# R7KA8D2AD register map
Vendor: Renesas Electronics Corporation; Series: RA8; File version: 1.10.02
CPU: CM85 r0p2, little endian, MPU, FPU, VTOR, 4 interrupt priority bits, 96 interrupts
Registers are 32-bit, read-write, reset 0x0 unless marked. A register's access mark holds for its fields unless they carry their own. Offsets are from the block's base; [hi:lo] are bit positions; {n}, {i} and the like mark numbered series; 'fields as' and 'values as' point back to an identical list.

## PDMIF — Pulse Density Modulator Interface
Base 0x40256000
Same registers: PDMIF_NS 0x50256000
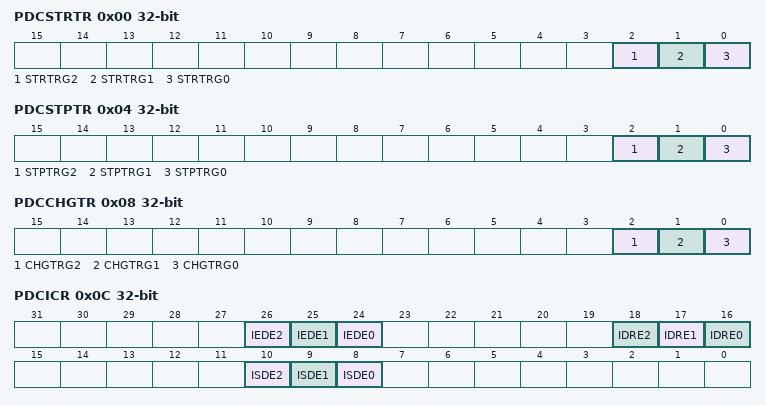
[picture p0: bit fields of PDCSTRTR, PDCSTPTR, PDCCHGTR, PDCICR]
0x00 PDCSTRTR wo — Channel Software Start Trigger Register
  [2] STRTRG2 — Channel 2 Start Trigger
    0=Do nothing; 1=Start channel 2
  [1] STRTRG1 — Channel 1 Start Trigger
    0=Do nothing; 1=Start channel 1
  [0] STRTRG0 — Channel 0 Start Trigger
    0=Do nothing; 1=Start channel 0
0x04 PDCSTPTR wo — Channel Software Stop Trigger Register
  [2] STPTRG2 — Channel 2 Stop Trigger
    0=Do nothing; 1=Stop channel 2
  [1] STPTRG1 — Channel 1 Stop Trigger
    0=Do nothing; 1=Stop channel 1
  [0] STPTRG0 — Channel 0 Stop Trigger
    0=Do nothing; 1=Stop channel 0
0x08 PDCCHGTR wo — Channel Software Change Trigger Register
  [2] CHGTRG2 — Channel 2 Change Trigger
    0=Do nothing; 1=Change clock (PDM_CLK2) setting
  [1] CHGTRG1 — Channel 1 Change Trigger
    0=Do nothing; 1=Change clock (PDM_CLK1) setting
  [0] CHGTRG0 — Channel 0 Change Trigger
    0=Do nothing; 1=Change clock (PDM_CLK0) setting
0x0C PDCICR — Channel Interrupt Control Register
  [26] IEDE2 — Channel 2 Error Detection Interrupt Enable Bit
    0=Do not allow PDM_ERR2 interrupt to be issued; 1=Allow PDM_ERR2 interrupt to be issued
  [25] IEDE1 — Channel 1 Error Detection Interrupt Enable Bit
    0=Do not allow PDM_ERR1 interrupt to be issued; 1=Allow PDM_ERR1 interrupt to be issued
  [24] IEDE0 — Channel 0 Error Detection Interrupt Enable Bit
    0=Do not allow PDM_ERR0 interrupt to be issued; 1=Allow PDM_ERR0 interrupt to be issued
  [18] IDRE2 — Channel 2 Data Reception Interrupt Enable Bit
    0=Do not allow PDM_DAT2 interrupt to be issued; 1=Allow PDM_DAT2 interrupt to be issued
  [17] IDRE1 — Channel 1 Data Reception Interrupt Enable Bit
    0=Do not allow PDM_DAT1 interrupt to be issued; 1=Allow PDM_DAT1 interrupt to be issued
  [16] IDRE0 — Channel 0 Data Reception Interrupt Enable Bit
    0=Do not allow PDM_DAT0 interrupt to be issued; 1=Allow PDM_DAT0 interrupt to be issued
  [10] ISDE2 — Channel 2 Sound Detection Interrupt Enable Bit
    0=Do not allow PDM_SDET interrupt to be issued when the sound for channel 2 is detected; 1=Allow PDM_SDET interrupt to be issued when the sound for channel 2 is detected
  [9] ISDE1 — Channel 1 Sound Detection Interrupt Enable Bit
    0=Do not allow PDM_SDET interrupt to be issued when the sound for channel 1 is detected; 1=Allow PDM_SDET interrupt to be issued when the sound for channel 1 is detected
  [8] ISDE0 — Channel 0 Sound Detection Interrupt Enable Bit
    0=Do not allow PDM_SDET interrupt to be issued when the sound for channel 0 is detected; 1=Allow PDM_SDET interrupt to be issued when the sound for channel 0 is detected
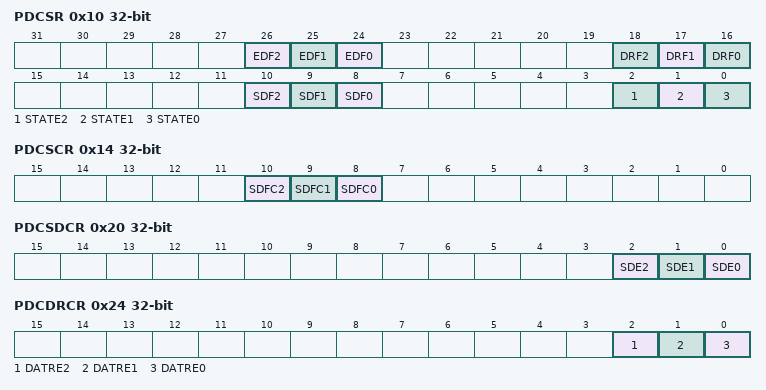
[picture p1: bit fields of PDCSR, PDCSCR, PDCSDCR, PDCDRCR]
0x10 PDCSR ro — Channel Status Register
  [26] EDF2 — Channel 2 Error Detection Flag
    0=Indicates that errors are not detected; 1=Indicates that errors are detected. See 1.2.17Status Register (PDSR) for details.
  [25] EDF1 — Channel 1 Error Detection Flag
    values as EDF2
  [24] EDF0 — Channel 0 Error Detection Flag
    values as EDF2
  [18] DRF2 — Channel 2 Data Reception Flag
    0=Indicates that the number of data stored in buffer does not exceed the threshold; 1=Indicates that the number of data stored in buffer exceeded the threshold
  [17] DRF1 — Channel 1 Data Reception Flag
    values as DRF2
  [16] DRF0 — Channel 0 Data Reception Flag
    values as DRF2
  [10] SDF2 — Channel 2 Sound Detection Flag
    0=Indicates that the sound which exceeded the threshold is not detected; 1=Indicates that the sound which exceeded the threshold is detected
  [9] SDF1 — Channel 1 Sound Detection Flag
    values as SDF2
  [8] SDF0 — Channel 0 Sound Detection Flag
    values as SDF2
  [2] STATE2 — Channel 2 State
    0=Channel 2 stop; 1=Channel 2 in operation
  [1] STATE1 — Channel 1 State
    0=Channel 1 stop; 1=Channel 1 in operation
  [0] STATE0 — Channel 0 State
    0=Channel 0 stop; 1=Channel 0 in operation
0x14 PDCSCR wo — Channel Status Clear Register
  [10] SDFC2 — Channel 2 Sound Detection Flag Clear
    0=Do nothing; 1=Clear PDCSR.SDF2
  [9] SDFC1 — Channel 1 Sound Detection Flag Clear
    0=Do nothing; 1=Clear PDCSR.SDF1
  [8] SDFC0 — Channel 0 Sound Detection Flag Clear
    0=Do nothing; 1=Clear PDCSR.SDF0
0x20 PDCSDCR — Channel Sound Detection Control Register
  [all] fields
    0=Do not allow sound detection; 1=Allow sound detection
  [2] SDE2 — Channel 2 Sound Detection Enable Bit
  [1] SDE1 — Channel 1 Sound Detection Enable Bit
  [0] SDE0 — Channel 0 Sound Detection Enable Bit
0x24 PDCDRCR — Channel Data Read Control Register
  [all] fields
    0=Do not allow reading data from data buffer; 1=Allow reading data from data buffer
  [2] DATRE2 — Channel 2 Data Read Enable Bit
  [1] DATRE1 — Channel 1 Data Read Enable Bit
  [0] DATRE0 — Channel 0 Data Read Enable Bit
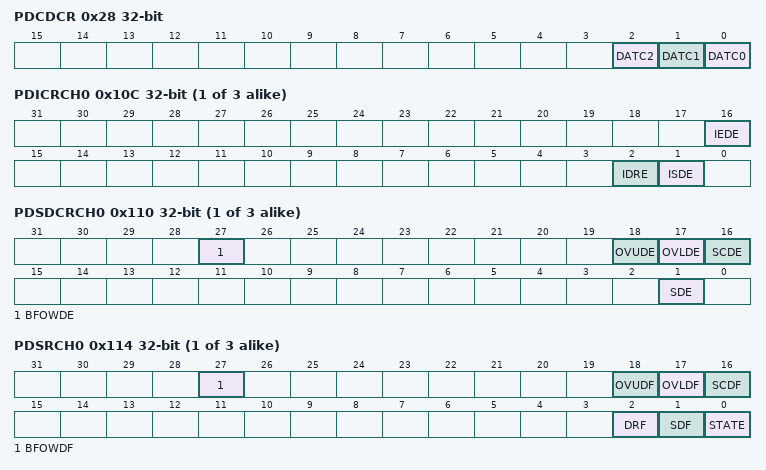
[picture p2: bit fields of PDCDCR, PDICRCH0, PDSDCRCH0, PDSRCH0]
0x28 PDCDCR wo — Channel Data Clear Register
  [all] fields
    0=Do nothing; 1=Clear data
  [2] DATC2 — Channel 2 Data Clear
  [1] DATC1 — Channel 1 Data Clear
  [0] DATC0 — Channel 0 Data Clear
0x80 PDVR ro reset 0x10 — Version Register
  [11:0] VER — PDM-IF version is shown.
{0x100+0x100*i} PDSTRTRCH{i} (i=0..2) wo — Software Start Trigger Register Channel {i}
  [0] STRTRG — Start Trigger
    0=Do nothing; 1=Start the channel
{0x104+0x100*i} PDSTPTRCH{i} (i=0..2) wo — Software Stop Trigger Register Channel {i}
  [0] STPTRG — Stop Trigger
    0=Do nothing; 1=Stop the channel
{0x108+0x100*i} PDCHGTRCH{i} (i=0..2) wo — Software Change Trigger Register Channel {i}
  [0] CHGTRG — Change Trigger
    0=Do nothing; 1=Change settings of PDM_CLKn and sinc filter
{0x10C+0x100*i} PDICRCH{i} (i=0..2) — Interrupt Control Register Channel {i}
  [16] IEDE — Error Detection Interrupt Enable Bit
    0=Do not allow PDM_ERRn interrupt to be issued; 1=Allow PDM_ERRn interrupt to be issued
  [2] IDRE — Data Reception Interrupt Enable Bit
    0=Do not allow PDM_DATn interrupt to be issued; 1=Allow PDM_DATn interrupt to be issued
  [1] ISDE — Sound Detection Interrupt Enable Bit
    0=Do not allow PDM_SDET interrupt to be issued; 1=Allow PDM_SDET interrupt to be issued
{0x110+0x100*i} PDSDCRCH{i} (i=0..2) — Status Detection Control Register Channel {i}
  [27] BFOWDE — Buffer Overwriting Detection Enable Bit
    0=Do not allow detection of buffer overwriting; 1=Allow detection of buffer overwriting
  [18] OVUDE — Overvoltage Upper Limit Exceeded Detection Enable Bit
    0=Do not allow detection of data exceeded upper limit; 1=Allow detection of data exceeded upper limit
  [17] OVLDE — Overvoltage Lower Limit Exceeded Detection Enable Bit
    0=Do not allow detection of data fallen lower limit; 1=Allow detection of data fallen lower limit
  [16] SCDE — Short Circuit Detection Enable Bit
    0=Do not allow detection of the PDM_DATAn pin short circuit; 1=Allow detection of the PDM_DATAn pin short circuit
  [1] SDE — Sound Detection Enable Bit
    0=Do not allow sound detection; 1=Allow sound detection
{0x114+0x100*i} PDSRCH{i} (i=0..2) ro — Status Register Channel {i}
  [27] BFOWDF — Buffer Overwriting Detection Flag
    0=Indicates that buffer overwriting does not occur; 1=Indicates that buffer overwriting occurs
  [18] OVUDF — Overvoltage Upper Limit Exceeded Detection Flag
    0=Indicates that the data has not exceeded the upper limit; 1=Indicates that the data has exceeded the upper limit
  [17] OVLDF — Overvoltage Lower Limit Exceeded Detection Flag
    0=Indicates that the data is not lower than the lower limit; 1=Indicates that the data has fallen the lower limit
  [16] SCDF — Short circuit detection flag.
    0=Indicates that the PDM_DATAn pin short circuit is not detected; 1=Indicates that a short circuit on the PDM_DATAn pin has been detected
  [2] DRF — Data Reception Flag
    0=Indicates that the number of data stored in buffer is lower than a threshold; 1=Indicates that the number of data stored in buffer is higher than or equal to a threshold
  [1] SDF — Sound Detection Flag
    0=Indicates that the sound is not detected; 1=Indicates that the sound is detected
  [0] STATE
    0=Channel stop; 1=Channel in operation
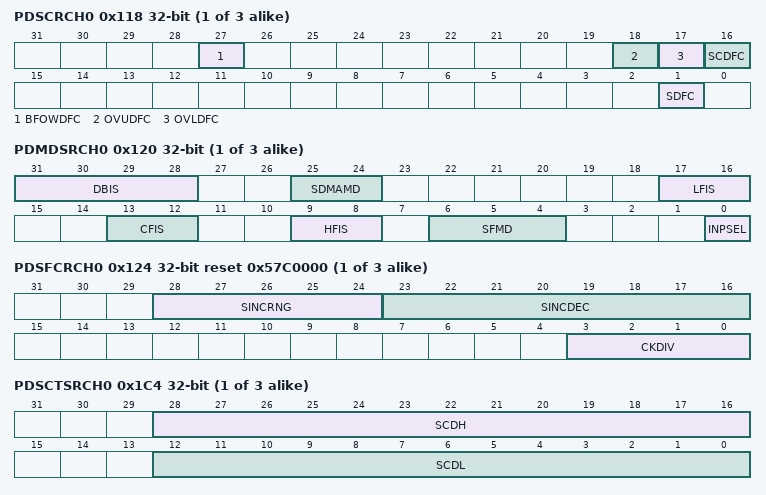
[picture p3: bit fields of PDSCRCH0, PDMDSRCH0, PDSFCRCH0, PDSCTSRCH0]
{0x118+0x100*i} PDSCRCH{i} (i=0..2) wo — Status Clear Register Channel {i}
  [27] BFOWDFC — Buffer Overwriting Detection Flag Clear
    0=Do nothing; 1=Clear PDSRCHn.BFOWDF
  [18] OVUDFC — Overvoltage Upper Limit Exceeded Detection Flag Clear
    0=Do nothing; 1=Clear PDSRCHn.OVUDF
  [17] OVLDFC — Overvoltage Lower Limit Exceeded Detection Flag Clear
    0=Do nothing; 1=Clear PDSRCHn.OVLDF
  [16] SCDFC — Short Circuit Detection Flag Clear
    0=Do nothing; 1=Clear PDSRCHn.SCDF
  [1] SDFC — Sound Detection Flag Clear
    0=Do nothing; 1=Clear PDSRCHn.SDF
{0x120+0x100*i} PDMDSRCH{i} (i=0..2) — Mode Setting Register Channel {i}
  [31:28] DBIS — Data Buffer Input Shift Setting
    0=20-bit mode, {1{S}, [18:0]}; 1=20-bit mode, {2{S}, [18:1]}; 2=20-bit mode, {3{S}, [18:2]}; 3=20-bit mode, {4{S}, [18:3]}; 8=16-bit mode, {S,D[18:4]}; 9=16-bit mode, {S,D[17:3]}; 10=16-bit mode, {S,D[16:2]}; 11=16-bit mode, {S,D[15:1]}; 12=16-bit mode, {S,D[14:0]}; other=Others (Setting prohibited)
  [25:24] SDMAMD — Moving Average Mode for Sound Detection Data
    0=1-order (filter is skipped) (default); 1=2-order; 2=4-order; 3=User prohibition
  [17:16] LFIS — Low-pass (half-band decimation) Filter Input Shift Setting
    0=No shift; 1=1-bit right shift; 2=2-bit right shift; 3=3-bit right shift
  [13:12] CFIS — Compensation Filter Input Shift Setting
    values as LFIS
  [9:8] HFIS — High-pass Filter Input Shift Setting
    values as LFIS
  [6:4] SFMD — Sinc Filter Mode Setting
    1=1-order; 2=2-order; 3=3-order; other=Others (4-order (default))
  [0] INPSEL — Input Data Select
    0=Rise-edge data of channel n; 1=Fall-edge data of channel n-1. When n = 0, fall-edge data of channel 2 is selected.
{0x124+0x100*i} PDSFCRCH{i} (i=0..2) reset 0x57C0000 — Sinc Filter Control Register Channel {i}
  [28:24] SINCRNG — Sinc Filter Output Valid Range
    0={S, [32:14]}; 1={S, [31:13]}; 2={S, [30:12]}; 3={S, [29:11]}; 4={S, [28:10]}; 5={S, [27:9]} (default); 6={S, [26:8]}; 7={S, [25:7]}; 8={S, [24:6]}; 9={S, [23:5]}; 10={S, [22:4]}; 11={S, [21:3]}; 12={S, [20:2]}; 13={S, [19:1]}; 14={S, [18:0]}; 15={S, [17:0], 0}; 16={S, [16:0], 00}; 17={S, [15:0], 000}; 18={S, [14:0], 0000}; 19={S, [13:0], 00000}; 20={S, [12:0], 000000}; 21={S, [11:0], 0000000}; 22={S, [10:0], 00000000}; 23={S, [9:0], 000000000}; 24={S, [8:0], 0000000000}; 25={S, [7:0], 00000000000}; 26={S, [6:0], 000000000000}; 27={S, [5:0], 0000000000000}; 28={S, [4:0], 00000000000000}; 29={S, [3:0], 000000000000000}; 30={S, [2:0], 0000000000000000}; 31={S, [1:0], 00000000000000000} (prohibited)
  [23:16] SINCDEC — Sinc Filter Decimation Ratio
  [3:0] CKDIV — PDM_CLKn Dividend Ratio to Core Clock
{0x128+0x100*i} PDHFCS0RCH{i} (i=0..2) reset 0x3F61 — High-pass Filter Coefficient s(0) Register Channel {i}
  [15:0] HFS — High-pass Filter Coefficient s(0)
{0x12C+0x100*i} PDHFCK1RCH{i} (i=0..2) reset 0x3EC1 — High-pass Filter Coefficient k(1) Register Channel {i}
  [15:0] HFK — High-pass Filter Coefficient k(1)
{0x130+0x100*i} PDHFCH0RCH{i} (i=0..2) reset 0x4000 — High-pass Filter Coefficient h(0) Register Channel {i}
  [15:0] HFH — High-pass Filter Coefficient h(0)
{0x134+0x100*i} PDHFCH1RCH{i} (i=0..2) reset 0xC000 — High-pass Filter Coefficient h(1) Register Channel {i}
  [15:0] HFH — High-pass Filter Coefficient h(1)
{0x138+0x100*i} PDCFCH00RCH{i} (i=0..2) reset 0x1FE8 — Compensation Filter Coefficient h(0) Register Channel {i}
  [12:0] CFH — Compensation Filter Coefficients h(0)
{0x13C+0x100*i} PDCFCH01RCH{i} (i=0..2) reset 0x39 — Compensation Filter Coefficient h(1) Register Channel {i}
  [12:0] CFH — Compensation Filter Coefficients h(1)
{0x140+0x100*i} PDCFCH02RCH{i} (i=0..2) reset 0x3C — Compensation Filter Coefficient h(2) Register Channel {i}
  [12:0] CFH — Compensation Filter Coefficients h(2)
{0x144+0x100*i} PDCFCH03RCH{i} (i=0..2) reset 0x1E56 — Compensation Filter Coefficient h(3) Register Channel {i}
  [12:0] CFH — Compensation Filter Coefficients h(3)
{0x148+0x100*i} PDCFCH04RCH{i} (i=0..2) reset 0x1DC — Compensation Filter Coefficient h(4) Register Channel {i}
  [12:0] CFH — Compensation Filter Coefficients h(4)
{0x14C+0x100*i} PDCFCH05RCH{i} (i=0..2) reset 0x6E1 — Compensation Filter Coefficient h(5) Register Channel {i}
  [12:0] CFH — Compensation Filter Coefficients h(5)
0x150 PDCFCH06RCHn reset 0x1DC — Compensation Filter Coefficient h(6) Register Channel n
  [12:0] CFH — Compensation Filter Coefficients h(6)
{0x154+0x100*i} PDCFCH07RCH{i} (i=0..2) reset 0x1E56 — Compensation Filter Coefficient h(7) Register Channel {i}
  [12:0] CFH — Compensation Filter Coefficients h(7)
{0x158+0x100*i} PDCFCH08RCH{i} (i=0..2) reset 0x3C — Compensation Filter Coefficient h(8) Register Channel {i}
  [12:0] CFH — Compensation Filter Coefficients h(8)
{0x15C+0x100*i} PDCFCH09RCH{i} (i=0..2) reset 0x39 — Compensation Filter Coefficient h(9) Register Channel {i}
  [12:0] CFH — Compensation Filter Coefficients h(9)
{0x160+0x100*i} PDCFCH10RCH{i} (i=0..2) reset 0x1FE8 — Compensation Filter Coefficient h(10) Register Channel {i}
  [12:0] CFH — Compensation Filter Coefficients h(10)
{0x164+0x100*i} PDLFCH010RCH{i} (i=0..2) reset 0x400 — Low-pass Filter Coefficient h0(10) Register Channel {i}
  [12:0] LFH0 — Low-pass (half-band decimation) Filter Coefficient h0(10)
{0x168+0x100*i} PDLFCH100RCH{i} (i=0..2) reset 0x1FF8 — Low-pass Filter Coefficient h1(0) Register Channel {i}
  [12:0] LFH1 — Low-pass (half-band decimation) Filter Coefficient h1(0)
{0x16C+0x100*i} PDLFCH101RCH{i} (i=0..2) reset 0xA — Low-pass Filter Coefficient h1(1) Register Channel {i}
  [12:0] LFH1 — Low-pass (half-band decimation) Filter Coefficient h1(1)
{0x170+0x100*i} PDLFCH102RCH{i} (i=0..2) reset 0x1FF0 — Low-pass Filter Coefficient h1 (2) Register Channel {i}
  [12:0] LFH1 — Low-pass (half-band decimation) Filter Coefficient h1(2)
{0x174+0x100*i} PDLFCH103RCH{i} (i=0..2) reset 0x18 — Low-pass Filter Coefficient h1(3) Register Channel {i}
  [12:0] LFH1 — Low-pass (half-band decimation) Filter Coefficient h1(3)
{0x178+0x100*i} PDLFCH104RCH{i} (i=0..2) reset 0x1FDC — Low-pass Filter Coefficient h1(4) Register Channel {i}
  [12:0] LFH1 — Low-pass (half-band decimation) Filter Coefficient h1(4)
{0x17C+0x100*i} PDLFCH105RCH{i} (i=0..2) reset 0x34 — Low-pass Filter Coefficient h1(5) Register Channel {i}
  [12:0] LFH1 — Low-pass (half-band decimation) Filter Coefficient h1(5)
{0x180+0x100*i} PDLFCH106RCH{i} (i=0..2) reset 0x1FB3 — Low-pass Filter Coefficient h1(6) Register Channel {i}
  [12:0] LFH1 — Low-pass (half-band decimation) Filter Coefficient h1(6)
{0x184+0x100*i} PDLFCH107RCH{i} (i=0..2) reset 0x76 — Low-pass Filter Coefficient h1(7) Register Channel {i}
  [12:0] LFH1 — Low-pass (half-band decimation) Filter Coefficient h1(7)
{0x188+0x100*i} PDLFCH108RCH{i} (i=0..2) reset 0x1F2E — Low-pass Filter Coefficient h1(8) Register Channel {i}
  [12:0] LFH1 — Low-pass (half-band decimation) Filter Coefficient h1(8)
{0x18C+0x100*i} PDLFCH109RCH{i} (i=0..2) reset 0x289 — Low-pass Filter Coefficient h1(9) Register Channel {i}
  [12:0] LFH1 — Low-pass (half-band decimation) Filter Coefficient h1(9)
{0x190+0x100*i} PDLFCH110RCH{i} (i=0..2) reset 0x289 — Low-pass Filter Coefficient h1(10) Register Channel {i}
  [12:0] LFH1 — Low-pass (half-band decimation) Filter Coefficient h1(10)
{0x194+0x100*i} PDLFCH111RCH{i} (i=0..2) reset 0x1F2E — Low-pass Filter Coefficient h1(11) Register Channel {i}
  [12:0] LFH1 — Low-pass (half-band decimation) Filter Coefficient h1(11)
{0x198+0x100*i} PDLFCH112RCH{i} (i=0..2) reset 0x76 — Low-pass Filter Coefficient h1(12) Register Channel {i}
  [12:0] LFH1 — Low-pass (half-band decimation) Filter Coefficient h1(12)
{0x19C+0x100*i} PDLFCH113RCH{i} (i=0..2) reset 0x1FB3 — Low-pass Filter Coefficient h1(13) Register Channel {i}
  [12:0] LFH1 — Low-pass (half-band decimation) Filter Coefficient h1(13)
{0x1A0+0x100*i} PDLFCH114RCH{i} (i=0..2) reset 0x34 — Low-pass Filter Coefficient h1(14) Register Channel {i}
  [12:0] LFH1 — Low-pass (half-band decimation) Filter Coefficient h1(14)
{0x1A4+0x100*i} PDLFCH115RCH{i} (i=0..2) reset 0x1FDC — Low-pass Filter Coefficient h1(15) Register Channel {i}
  [12:0] LFH1 — Low-pass (half-band decimation) Filter Coefficient h1(15)
{0x1A8+0x100*i} PDLFCH116RCH{i} (i=0..2) reset 0x18 — Low-pass Filter Coefficient h1(16) Register Channel {i}
  fields as PDLFCH115RCH0
{0x1AC+0x100*i} PDLFCH117RCH{i} (i=0..2) reset 0x1FF0 — Low-pass Filter Coefficient h1(17) Register Channel {i}
  [12:0] LFH1 — Low-pass (half-band decimation) Filter Coefficient h1(17)
{0x1B0+0x100*i} PDLFCH118RCH{i} (i=0..2) reset 0xA — Low-pass Filter Coefficient h1(18) Register Channel {i}
  [12:0] LFH1 — Low-pass (half-band decimation) Filter Coefficient h1(18)
{0x1B4+0x100*i} PDLFCH119RCH{i} (i=0..2) reset 0x1FF8 — Low-pass Filter Coefficient h1(19) Register Channel {i}
  [12:0] LFH1 — Low-pass (half-band decimation) Filter Coefficient h1(19)
{0x1B8+0x100*i} PDSDLTRCH{i} (i=0..2) — Sound Detection Lower Threshold Register Channel {i}
  [19:0] SDETL — Sound Detection Lower Limit
{0x1BC+0x100*i} PDSDUTRCH{i} (i=0..2) — Sound Detection Upper Threshold Register Channel {i}
  [19:0] SDETU — Sound Detection Upper Limit
{0x1C0+0x100*i} PDDBCRCH{i} (i=0..2) — Data Buffer Control Register Channel {i}
  [2:0] DATRITHR — Data Reception Interrupt Threshold
    0=Output interrupt when receiving 1 or more data; 1=Output interrupt when receiving 2 or more data; 2=Output interrupt when receiving 4 or more data; 3=Output interrupt when receiving 8 or more data; other=Others (Output interrupt when receiving 16 or more data)
{0x1C4+0x100*i} PDSCTSRCH{i} (i=0..2) — Short Circuit Threshold Setting Register Channel {i}
  [28:16] SCDH — Short Circuit Detection High Continuous Detection Count
  [12:0] SCDL — Short Circuit Detection Low Continuous Detection Count
{0x1C8+0x100*i} PDOVLTRCH{i} (i=0..2) — Overvoltage Lower Threshold Register Channel {i}
  [19:0] OVDL — Overvoltage Detection Lower Limit
{0x1CC+0x100*i} PDOVUTRCH{i} (i=0..2) — Overvoltage Upper Threshold Register Channel {i}
  [19:0] OVDU — Overvoltage Detection Upper Limit
{0x1E0+0x100*i} PDDRCRCH{i} (i=0..2) — Data Read Control Register Channel {i}
  [0] DATRE — Data Read Enable Bit
    0=Do not allow reading of data from buffer; 1=Allow reading of data from buffer
{0x1E4+0x100*i} PDDCRCH{i} (i=0..2) wo — Data Clear Register Channel {i}
  [0] DATC — Data Clear
    0=Do nothing; 1=Clear data
{0x1E8+0x100*i} PDDRRCH{i} (i=0..2) ro — Data Read Register Channel {i}
  [19:0] DAT — Data
{0x1EC+0x100*i} PDDSRCH{i} (i=0..2) ro — Data Status Register Channel {i}
  [7:0] DATNUM — Number of Data Stored in Buffer
